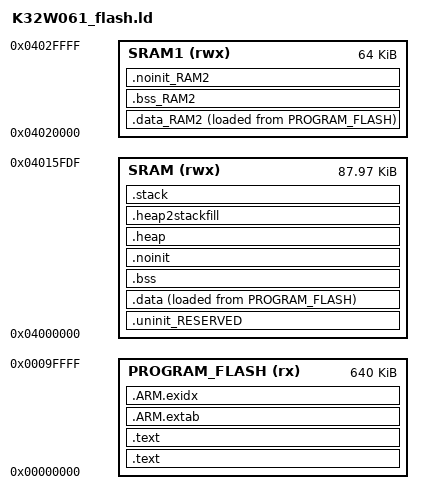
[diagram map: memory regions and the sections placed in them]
/*
 * GENERATED FILE - DO NOT EDIT
 * Copyright (c) 2008-2013 Code Red Technologies Ltd,
 * Copyright 2015, 2018-2019 NXP
 * (c) NXP Semiconductors 2013-2020
 * Generated linker script file for K32W061
 * Created from linkscript.ldt by FMCreateLinkLibraries
 * Using Freemarker v2.3.23
 * MCUXpresso IDE v11.2.0 [Build 4120] [2020-07-09] on Oct 29, 2020 5:50:09 PM
 */

GROUP (
  "libcr_semihost_nf.a"
  "libcr_c.a"
  "libcr_eabihelpers.a"
  "libgcc.a"
)

MEMORY
{
  /* Define each memory region */
  PROGRAM_FLASH (rx) : ORIGIN = 0x0, LENGTH = 0xa0000 /* 640K bytes (alias Flash) */
  SRAM (rwx) : ORIGIN = 0x4000000, LENGTH = 0x15fe0 /* 90080 bytes (alias RAM) */
  SRAM1 (rwx) : ORIGIN = 0x4020000, LENGTH = 0x10000 /* 64K bytes (alias RAM2) */
}

  /* Define a symbol for the top of each memory region */
  __base_PROGRAM_FLASH = 0x0  ; /* PROGRAM_FLASH */
  __base_Flash = 0x0 ; /* Flash */
  __top_PROGRAM_FLASH = 0x0 + 0xa0000 ; /* 640K bytes */
  __top_Flash = 0x0 + 0xa0000 ; /* 640K bytes */
  __base_SRAM = 0x4000000  ; /* SRAM */
  __base_RAM = 0x4000000 ; /* RAM */
  __top_SRAM = 0x4000000 + 0x15fe0 ; /* 90080 bytes */
  __top_RAM = 0x4000000 + 0x15fe0 ; /* 90080 bytes */
  __base_SRAM1 = 0x4020000  ; /* SRAM1 */
  __base_RAM2 = 0x4020000 ; /* RAM2 */
  __top_SRAM1 = 0x4020000 + 0x10000 ; /* 64K bytes */
  __top_RAM2 = 0x4020000 + 0x10000 ; /* 64K bytes */


ENTRY(ResetISR)

SECTIONS
{
     /* MAIN TEXT SECTION */
    .text : ALIGN(4)
    {
        FILL(0xff)
        __vectors_start__ = ABSOLUTE(.) ;
        KEEP(*(.isr_vector))
        /* Global Section Table */
        . = ALIGN(4) ;
        __section_table_start = .;
        __data_section_table = .;
        LONG(LOADADDR(.data));
        LONG(    ADDR(.data));
        LONG(  SIZEOF(.data));
        LONG(LOADADDR(.data_RAM2));
        LONG(    ADDR(.data_RAM2));
        LONG(  SIZEOF(.data_RAM2));
        __data_section_table_end = .;
        __bss_section_table = .;
        LONG(    ADDR(.bss));
        LONG(  SIZEOF(.bss));
        LONG(    ADDR(.bss_RAM2));
        LONG(  SIZEOF(.bss_RAM2));
        __bss_section_table_end = .;
        __section_table_end = . ;
        /* End of Global Section Table */

        *(.after_vectors*)

    } > PROGRAM_FLASH

    .text : ALIGN(4)
    {
       *(.text*)
       *(.rodata .rodata.* .constdata .constdata.*)
       . = ALIGN(4);
    } > PROGRAM_FLASH
    /*
     * for exception handling/unwind - some Newlib functions (in common
     * with C++ and STDC++) use this.
     */
    .ARM.extab : ALIGN(4)
    {
        *(.ARM.extab* .gnu.linkonce.armextab.*)
    } > PROGRAM_FLASH

    .ARM.exidx : ALIGN(4)
    {
        __exidx_start = .;
        *(.ARM.exidx* .gnu.linkonce.armexidx.*)
        __exidx_end = .;
    } > PROGRAM_FLASH

    _etext = .;

    /* DATA section for SRAM1 */

    .data_RAM2 : ALIGN(4)
    {
        FILL(0xff)
        PROVIDE(__start_data_RAM2 = .) ;
        PROVIDE(__start_data_SRAM1 = .) ;
        *(.ramfunc.$RAM2)
        *(.ramfunc.$SRAM1)
        *(.data.$RAM2)
        *(.data.$SRAM1)
        *(.data.$RAM2.*)
        *(.data.$SRAM1.*)
        . = ALIGN(4) ;
        PROVIDE(__end_data_RAM2 = .) ;
        PROVIDE(__end_data_SRAM1 = .) ;
     } > SRAM1 AT>PROGRAM_FLASH

    /* MAIN DATA SECTION */
    .uninit_RESERVED (NOLOAD) : ALIGN(4)
    {
        _start_uninit_RESERVED = .;
        KEEP(*(.bss.$RESERVED*))
       . = ALIGN(4) ;
        _end_uninit_RESERVED = .;
    } > SRAM AT> SRAM

    /* Main DATA section (SRAM) */
    .data : ALIGN(4)
    {
       FILL(0xff)
       _data = . ;
       PROVIDE(__start_data_RAM = .) ;
       PROVIDE(__start_data_SRAM = .) ;
       *(vtable)
       *(.ramfunc*)
       KEEP(*(CodeQuickAccess))
       KEEP(*(DataQuickAccess))
       *(RamFunction)
       *(.data*)
       . = ALIGN(4) ;
       _edata = . ;
       PROVIDE(__end_data_RAM = .) ;
       PROVIDE(__end_data_SRAM = .) ;
    } > SRAM AT>PROGRAM_FLASH

    /* BSS section for SRAM1 */
    .bss_RAM2 : ALIGN(4)
    {
       PROVIDE(__start_bss_RAM2 = .) ;
       PROVIDE(__start_bss_SRAM1 = .) ;
       *(.bss.$RAM2)
       *(.bss.$SRAM1)
       *(.bss.$RAM2.*)
       *(.bss.$SRAM1.*)
       . = ALIGN (. != 0 ? 4 : 1) ; /* avoid empty segment */
       PROVIDE(__end_bss_RAM2 = .) ;
       PROVIDE(__end_bss_SRAM1 = .) ;
    } > SRAM1 AT> SRAM1

    /* MAIN BSS SECTION */
    .bss : ALIGN(4)
    {
        _bss = .;
        PROVIDE(__start_bss_RAM = .) ;
        PROVIDE(__start_bss_SRAM = .) ;
        *(.bss*)
        *(COMMON)
        . = ALIGN(4) ;
        _ebss = .;
        PROVIDE(__end_bss_RAM = .) ;
        PROVIDE(__end_bss_SRAM = .) ;
        PROVIDE(end = .);
    } > SRAM AT> SRAM

    /* NOINIT section for SRAM1 */
    .noinit_RAM2 (NOLOAD) : ALIGN(4)
    {
       PROVIDE(__start_noinit_RAM2 = .) ;
       PROVIDE(__start_noinit_SRAM1 = .) ;
       *(.noinit.$RAM2)
       *(.noinit.$SRAM1)
       *(.noinit.$RAM2.*)
       *(.noinit.$SRAM1.*)
       . = ALIGN(4) ;
       PROVIDE(__end_noinit_RAM2 = .) ;
       PROVIDE(__end_noinit_SRAM1 = .) ;
    } > SRAM1 AT> SRAM1

    /* DEFAULT NOINIT SECTION */
    .noinit (NOLOAD): ALIGN(4)
    {
        _noinit = .;
        PROVIDE(__start_noinit_RAM = .) ;
        PROVIDE(__start_noinit_SRAM = .) ;
        *(.noinit*)
         . = ALIGN(4) ;
        _end_noinit = .;
       PROVIDE(__end_noinit_RAM = .) ;
       PROVIDE(__end_noinit_SRAM = .) ;
    } > SRAM AT> SRAM

    /* Reserve and place Heap within memory map */
    _HeapSize = 0x1000;
    .heap :  ALIGN(4)
    {
        _pvHeapStart = .;
        . += _HeapSize;
        . = ALIGN(4);
        _pvHeapLimit = .;
    } > SRAM

     _StackSize = 0x1000;
     /* Reserve space in memory for Stack */
    .heap2stackfill  :
    {
        . += _StackSize;
    } > SRAM
    /* Locate actual Stack in memory map */
    .stack ORIGIN(SRAM) + LENGTH(SRAM) - _StackSize - 0:  ALIGN(4)
    {
        _vStackBase = .;
        . = ALIGN(4);
        _vStackTop = . + _StackSize;
    } > SRAM

    /* Provide basic symbols giving location and size of main text
     * block, including initial values of RW data sections. Note that
     * these will need extending to give a complete picture with
     * complex images (e.g multiple Flash banks).
     */
    _image_start = LOADADDR(.text);
    _image_end = LOADADDR(.data) + SIZEOF(.data);
    _image_size = _image_end - _image_start;
}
